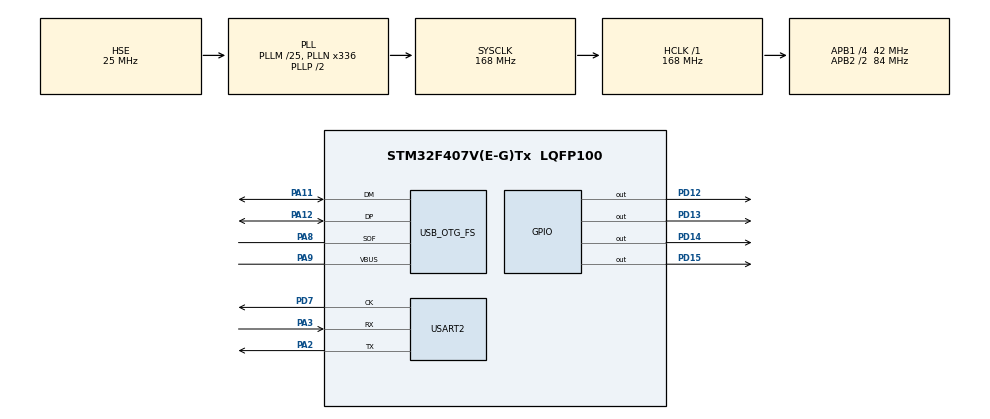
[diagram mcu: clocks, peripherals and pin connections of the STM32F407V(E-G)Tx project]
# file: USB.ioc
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Mcu.Family=STM32F4
Mcu.Name=STM32F407V(E-G)Tx
Mcu.Package=LQFP100
NVIC.OTG_FS_IRQn=true\:0\:0\:false\:false\:true\:false
NVIC.PriorityGroup=NVIC_PRIORITYGROUP_4
PA11.Mode=Host_Only
PA11.Signal=USB_OTG_FS_DM
PA12.Mode=Host_Only
PA12.Signal=USB_OTG_FS_DP
PA13.Mode=Serial_Wire
PA13.Signal=SYS_JTMS-SWDIO
PA14.Mode=Serial_Wire
PA14.Signal=SYS_JTCK-SWCLK
PA2.Mode=Synchronous
PA2.Signal=USART2_TX
PA3.Mode=Synchronous
PA3.Signal=USART2_RX
PA8.Mode=Activate_SOF_FS
PA8.Signal=USB_OTG_FS_SOF
PA9.Mode=Activate_VBUS
PA9.Signal=USB_OTG_FS_VBUS
PD12.Signal=GPIO_Output
PD13.Signal=GPIO_Output
PD14.Signal=GPIO_Output
PD15.Signal=GPIO_Output
PD7.Mode=Synchronous
PD7.Signal=USART2_CK
PH0-OSC_IN.Mode=HSE-External-Oscillator
PH0-OSC_IN.Signal=RCC_OSC_IN
PH1-OSC_OUT.Mode=HSE-External-Oscillator
PH1-OSC_OUT.Signal=RCC_OSC_OUT
ProjectManager.HeapSize=0x200
ProjectManager.StackSize=0x400
ProjectManager.TargetToolchain=SW4STM32
RCC.48MHZClocksFreq_Value=48000000
RCC.AHBFreq_Value=168000000
RCC.APB1CLKDivider=RCC_HCLK_DIV4
RCC.APB1Freq_Value=42000000
RCC.APB1TimFreq_Value=84000000
RCC.APB2CLKDivider=RCC_HCLK_DIV2
RCC.APB2Freq_Value=84000000
RCC.APB2TimFreq_Value=168000000
RCC.CortexFreq_Value=168000000
RCC.HCLKFreq_Value=168000000
RCC.HSE_VALUE=25000000
RCC.HSI_VALUE=16000000
RCC.LSE_VALUE=32768
RCC.PLLM=25
RCC.PLLN=336
RCC.PLLQ=7
RCC.SYSCLKFreq_VALUE=168000000
RCC.SYSCLKSource=RCC_SYSCLKSOURCE_PLLCLK
RCC.VCOOutputFreq_Value=336000000
USART2.VirtualMode=VM_SYNC
USB_HOST.USBH_HandleTypeDef-HID_FS=hUsbHostFS
USB_HOST.VirtualModeFS=Hid
USB_OTG_FS.VirtualMode=Host_Only
USB_OTG_FS.phy_itface=HCD_PHY_EMBEDDED
VP_USB_HOST_VS_USB_HOST_HID_FS.Mode=HID_FS
board=USB

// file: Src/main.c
/**
  ******************************************************************************
  * File Name          : main.c
  * Description        : Main program body
  ******************************************************************************
  * This notice applies to any and all portions of this file
  * that are not between comment pairs USER CODE BEGIN and
  * USER CODE END. Other portions of this file, whether
  * inserted by the user or by software development tools
  * are owned by their respective copyright owners.
  *
  * Copyright (c) 2018 STMicroelectronics International N.V.
  * All rights reserved.
  *
  * Redistribution and use in source and binary forms, with or without
  * modification, are permitted, provided that the following conditions are met:
  *
  * 1. Redistribution of source code must retain the above copyright notice,
  *    this list of conditions and the following disclaimer.
  * 2. Redistributions in binary form must reproduce the above copyright notice,
  *    this list of conditions and the following disclaimer in the documentation
  *    and/or other materials provided with the distribution.
  * 3. Neither the name of STMicroelectronics nor the names of other
  *    contributors to this software may be used to endorse or promote products
  *    derived from this software without specific written permission.
  * 4. This software, including modifications and/or derivative works of this
  *    software, must execute solely and exclusively on microcontroller or
  *    microprocessor devices manufactured by or for STMicroelectronics.
  * 5. Redistribution and use of this software other than as permitted under
  *    this license is void and will automatically terminate your rights under
  *    this license.
  *
  * THIS SOFTWARE IS PROVIDED BY STMICROELECTRONICS AND CONTRIBUTORS "AS IS"
  * AND ANY EXPRESS, IMPLIED OR STATUTORY WARRANTIES, INCLUDING, BUT NOT
  * LIMITED TO, THE IMPLIED WARRANTIES OF MERCHANTABILITY, FITNESS FOR A
  * PARTICULAR PURPOSE AND NON-INFRINGEMENT OF THIRD PARTY INTELLECTUAL PROPERTY
  * RIGHTS ARE DISCLAIMED TO THE FULLEST EXTENT PERMITTED BY LAW. IN NO EVENT
  * SHALL STMICROELECTRONICS OR CONTRIBUTORS BE LIABLE FOR ANY DIRECT, INDIRECT,
  * INCIDENTAL, SPECIAL, EXEMPLARY, OR CONSEQUENTIAL DAMAGES (INCLUDING, BUT NOT
  * LIMITED TO, PROCUREMENT OF SUBSTITUTE GOODS OR SERVICES; LOSS OF USE, DATA,
  * OR PROFITS; OR BUSINESS INTERRUPTION) HOWEVER CAUSED AND ON ANY THEORY OF
  * LIABILITY, WHETHER IN CONTRACT, STRICT LIABILITY, OR TORT (INCLUDING
  * NEGLIGENCE OR OTHERWISE) ARISING IN ANY WAY OUT OF THE USE OF THIS SOFTWARE,
  * EVEN IF ADVISED OF THE POSSIBILITY OF SUCH DAMAGE.
  *
  ******************************************************************************
  */
#include "main.h"
#include "stm32f4xx_hal.h"
#include "stm32f4xx_hal_usart.h"
#include "usb_host.h"

/* USER CODE BEGIN Includes */
#include "usbh_hid_mouse.h"
#include "usbh_hid_keybd.h"

#define XN_ON  HAL_GPIO_WritePin(GPIOD,GPIO_PIN_12,GPIO_PIN_SET);	//Saida 0 ON
#define XN_OFF HAL_GPIO_WritePin(GPIOD,GPIO_PIN_12,GPIO_PIN_RESET);	//Saida 0 OFF
#define YP_ON  HAL_GPIO_WritePin(GPIOD,GPIO_PIN_13,GPIO_PIN_SET);	//Saida 1 ON
#define YP_OFF HAL_GPIO_WritePin(GPIOD,GPIO_PIN_13,GPIO_PIN_RESET);	//Saida 1 OFF
#define XP_ON  HAL_GPIO_WritePin(GPIOD,GPIO_PIN_14,GPIO_PIN_SET);	//Saida 2 ON
#define XP_OFF HAL_GPIO_WritePin(GPIOD,GPIO_PIN_14,GPIO_PIN_RESET);	//Saida 2 OFF
#define YN_ON  HAL_GPIO_WritePin(GPIOD,GPIO_PIN_15,GPIO_PIN_SET);	//Saida 3 ON
#define YN_OFF HAL_GPIO_WritePin(GPIOD,GPIO_PIN_15,GPIO_PIN_RESET);	//Saida 3 OFF
/* USER CODE END Includes */

USART_HandleTypeDef husart2;

extern HID_MOUSE_Info_TypeDef    *mouse_info;
extern HID_KEYBD_Info_TypeDef     *keybd_info;
uint8_t buffer[4];
/* USER CODE END PV */

void SystemClock_Config(void);
static void MX_GPIO_Init(void);
static void MX_USART2_Init(void);
void MX_USB_HOST_Process(void);

/* USER CODE BEGIN PFP */
/* Private function prototypes -----------------------------------------------*/

/* USER CODE END PFP */

int main(void)
{
  /* STM32F4xx HAL library initialization:
       - Configure the Flash prefetch, instruction and Data caches
       - Configure the Systick to generate an interrupt each 1 msec
       - Set NVIC Group Priority to 4
       - Global MSP (MCU Support Package) initialization
     */
  HAL_Init();

  /* Configure the system clock to 120 MHz */
  SystemClock_Config();

  MX_GPIO_Init();
  MX_USART2_Init();
  MX_USB_HOST_Init();

  /* Run Application (Blocking mode) */
  while (1)
  {
    /* USB Host Background task */
    MX_USB_HOST_Process();

  }
}

/** System Clock Configuration
*/
void SystemClock_Config(void)
{

  RCC_OscInitTypeDef RCC_OscInitStruct;
  RCC_ClkInitTypeDef RCC_ClkInitStruct;

    /**Configure the main internal regulator output voltage
    */
  __HAL_RCC_PWR_CLK_ENABLE();

  __HAL_PWR_VOLTAGESCALING_CONFIG(PWR_REGULATOR_VOLTAGE_SCALE1);

    /**Initializes the CPU, AHB and APB busses clocks
    */
  RCC_OscInitStruct.OscillatorType = RCC_OSCILLATORTYPE_HSE;
  RCC_OscInitStruct.HSEState = RCC_HSE_ON;
  RCC_OscInitStruct.PLL.PLLState = RCC_PLL_ON;
  RCC_OscInitStruct.PLL.PLLSource = RCC_PLLSOURCE_HSE;
  RCC_OscInitStruct.PLL.PLLM = 25;
  RCC_OscInitStruct.PLL.PLLN = 336;
  RCC_OscInitStruct.PLL.PLLP = RCC_PLLP_DIV2;
  RCC_OscInitStruct.PLL.PLLQ = 7;
  if (HAL_RCC_OscConfig(&RCC_OscInitStruct) != HAL_OK)
  {
    _Error_Handler(__FILE__, __LINE__);
  }

    /**Initializes the CPU, AHB and APB busses clocks
    */
  RCC_ClkInitStruct.ClockType = RCC_CLOCKTYPE_HCLK|RCC_CLOCKTYPE_SYSCLK
                              |RCC_CLOCKTYPE_PCLK1|RCC_CLOCKTYPE_PCLK2;
  RCC_ClkInitStruct.SYSCLKSource = RCC_SYSCLKSOURCE_PLLCLK;
  RCC_ClkInitStruct.AHBCLKDivider = RCC_SYSCLK_DIV1;
  RCC_ClkInitStruct.APB1CLKDivider = RCC_HCLK_DIV4;
  RCC_ClkInitStruct.APB2CLKDivider = RCC_HCLK_DIV2;

  if (HAL_RCC_ClockConfig(&RCC_ClkInitStruct, FLASH_LATENCY_5) != HAL_OK)
  {
    _Error_Handler(__FILE__, __LINE__);
  }

    /**Configure the Systick interrupt time
    */
  HAL_SYSTICK_Config(HAL_RCC_GetHCLKFreq()/1000);

    /**Configure the Systick
    */
  HAL_SYSTICK_CLKSourceConfig(SYSTICK_CLKSOURCE_HCLK);

  /* SysTick_IRQn interrupt configuration */
  HAL_NVIC_SetPriority(SysTick_IRQn, 0, 0);
}

/* USART2 init function */
static void MX_USART2_Init(void)
{

  husart2.Instance = USART2;
  husart2.Init.BaudRate = 115200;
  husart2.Init.WordLength = USART_WORDLENGTH_8B;
  husart2.Init.StopBits = USART_STOPBITS_1;
  husart2.Init.Parity = USART_PARITY_NONE;
  husart2.Init.Mode = USART_MODE_TX_RX;
  husart2.Init.CLKPolarity = USART_POLARITY_LOW;
  husart2.Init.CLKPhase = USART_PHASE_1EDGE;
  husart2.Init.CLKLastBit = USART_LASTBIT_DISABLE;
  if (HAL_USART_Init(&husart2) != HAL_OK)
  {
    _Error_Handler(__FILE__, __LINE__);
  }

}

/** Configure pins as
        * Analog
        * Input
        * Output
        * EVENT_OUT
        * EXTI
*/
static void MX_GPIO_Init(void)
{

  GPIO_InitTypeDef GPIO_InitStruct;

  /* GPIO Ports Clock Enable */
  __HAL_RCC_GPIOH_CLK_ENABLE();
  __HAL_RCC_GPIOA_CLK_ENABLE();
  __HAL_RCC_GPIOD_CLK_ENABLE();
  __HAL_RCC_GPIOB_CLK_ENABLE();
  __HAL_RCC_GPIOC_CLK_ENABLE();

  HAL_GPIO_WritePin(OTG_FS_PowerSwitchOn_GPIO_Port, OTG_FS_PowerSwitchOn_Pin, GPIO_PIN_SET);

	  GPIO_InitStruct.Pin = GPIO_PIN_0;
	  GPIO_InitStruct.Mode = GPIO_MODE_OUTPUT_PP;
	  GPIO_InitStruct.Pull = GPIO_NOPULL;
	  GPIO_InitStruct.Speed = GPIO_SPEED_FREQ_LOW;
	  HAL_GPIO_Init(GPIOC, &GPIO_InitStruct);

  /*Configure GPIO pin Output Level */
  HAL_GPIO_WritePin(GPIOD, GPIO_PIN_12|GPIO_PIN_13|GPIO_PIN_14|GPIO_PIN_15, GPIO_PIN_RESET);

  /*Configure GPIO pins : PD12 PD13 PD14 PD15 */
  GPIO_InitStruct.Pin = GPIO_PIN_12|GPIO_PIN_13|GPIO_PIN_14|GPIO_PIN_15;
  GPIO_InitStruct.Mode = GPIO_MODE_OUTPUT_PP;
  GPIO_InitStruct.Pull = GPIO_NOPULL;
  GPIO_InitStruct.Speed = GPIO_SPEED_FREQ_LOW;
  HAL_GPIO_Init(GPIOD, &GPIO_InitStruct);

}

void _Error_Handler(char * file, int line)
{
  while(1)
  {
  }
}

/************************ (C) COPYRIGHT STMicroelectronics *****END OF FILE****/
